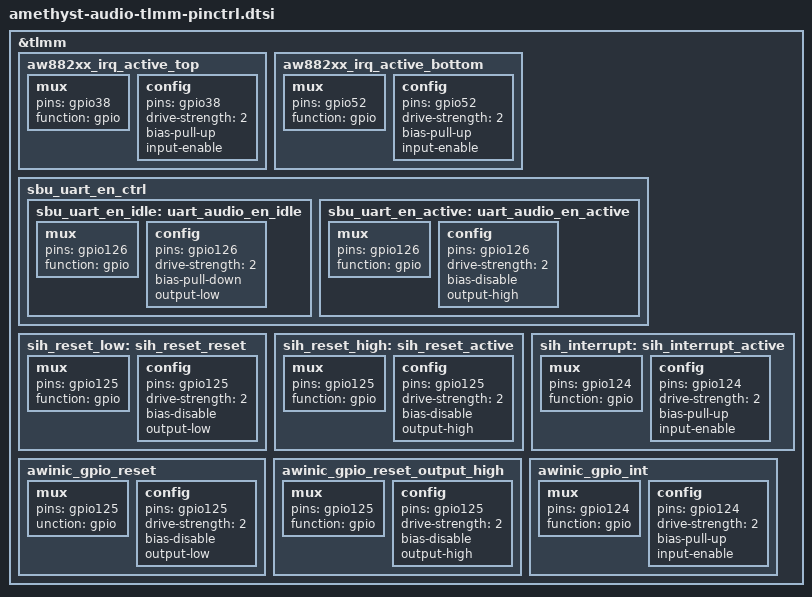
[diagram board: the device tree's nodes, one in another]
/*
 * Amethyst TLMM pin states for the AW882xx smart PAs, the Awinic and SIH
 * haptics drivers and the SBU UART enable line.
 *
 * Reconstructed from stock dtbo.img (dtbo.img:1, fragments 43) with
 * scripts/amethyst-dtbo-to-dts.py; labels and references are the stock
 * ones from __symbols__, __fixups__ and __local_fixups__.
 */

&tlmm {
	aw882xx_irq_active_top: aw882xx_irq_active_top {

		mux {
			pins = "gpio38";
			function = "gpio";
		};

		config {
			pins = "gpio38";
			drive-strength = <2>;
			bias-pull-up;
			input-enable;
		};
	};
	aw882xx_irq_active_bottom: aw882xx_irq_active_bottom {

		mux {
			pins = "gpio52";
			function = "gpio";
		};

		config {
			pins = "gpio52";
			drive-strength = <2>;
			bias-pull-up;
			input-enable;
		};
	};
	sbu_uart_en_ctrl {
		sbu_uart_en_idle: uart_audio_en_idle {

			mux {
				pins = "gpio126";
				function = "gpio";
			};

			config {
				pins = "gpio126";
				drive-strength = <2>;
				bias-pull-down;
				output-low;
			};
		};
		sbu_uart_en_active: uart_audio_en_active {

			mux {
				pins = "gpio126";
				function = "gpio";
			};

			config {
				pins = "gpio126";
				drive-strength = <2>;
				bias-disable;
				output-high;
			};
		};
	};
	sih_reset_low: sih_reset_reset {

		mux {
			pins = "gpio125";
			function = "gpio";
		};

		config {
			pins = "gpio125";
			drive-strength = <2>;
			bias-disable;
			output-low;
		};
	};
	sih_reset_high: sih_reset_active {

		mux {
			pins = "gpio125";
			function = "gpio";
		};

		config {
			pins = "gpio125";
			drive-strength = <2>;
			bias-disable;
			output-high;
		};
	};
	sih_interrupt: sih_interrupt_active {

		mux {
			pins = "gpio124";
			function = "gpio";
		};

		config {
			pins = "gpio124";
			drive-strength = <2>;
			bias-pull-up;
			input-enable;
		};
	};
	awinic_gpio_reset: awinic_gpio_reset {

		mux {
			pins = "gpio125";
			unction = "gpio";
		};

		config {
			pins = "gpio125";
			drive-strength = <2>;
			bias-disable;
			output-low;
		};
	};
	awinic_gpio_reset_output_high: awinic_gpio_reset_output_high {

		mux {
			pins = "gpio125";
			function = "gpio";
		};

		config {
			pins = "gpio125";
			drive-strength = <2>;
			bias-disable;
			output-high;
		};
	};
	awinic_gpio_int: awinic_gpio_int {

		mux {
			pins = "gpio124";
			function = "gpio";
		};

		config {
			pins = "gpio124";
			drive-strength = <2>;
			bias-pull-up;
			input-enable;
		};
	};
};
